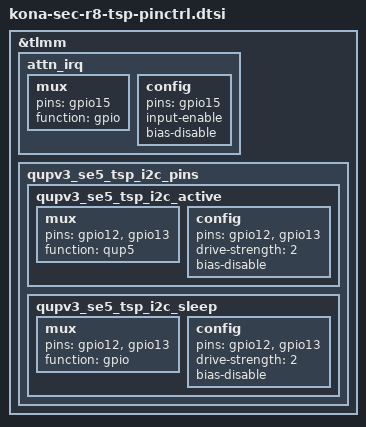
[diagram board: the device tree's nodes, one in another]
/* Copyright (c) 2019, The Linux Foundation. All rights reserved.
 *
 * This program is free software; you can redistribute it and/or modify
 * it under the terms of the GNU General Public License version 2 and
 * only version 2 as published by the Free Software Foundation.
 *
 * This program is distributed in the hope that it will be useful,
 * but WITHOUT ANY WARRANTY; without even the implied warranty of
 * MERCHANTABILITY or FITNESS FOR A PARTICULAR PURPOSE.  See the
 * GNU General Public License for more details.
 */

&tlmm {
	attn_irq: attn_irq {
		mux {
			pins = "gpio15";
			function = "gpio";
		};
		config {
			pins = "gpio15";
			input-enable;
			bias-disable;
		};
	};

	/* SE 5 pin mappings */
	qupv3_se5_tsp_i2c_pins: qupv3_se5_tsp_i2c_pins {
		qupv3_se5_tsp_i2c_active: qupv3_se5_tsp_i2c_active {
			mux {
				pins = "gpio12", "gpio13";
				function = "qup5";
			};

			config {
				pins = "gpio12", "gpio13";
				drive-strength = <2>;
				bias-disable;
			};
		};

		qupv3_se5_tsp_i2c_sleep: qupv3_se5_tsp_i2c_sleep {
			mux {
				pins = "gpio12", "gpio13";
				function = "gpio";
			};

			config {
				pins = "gpio12", "gpio13";
				drive-strength = <2>;
				bias-disable;
			};
		};
	};
};
